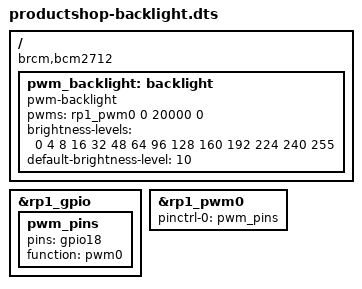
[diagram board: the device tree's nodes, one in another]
/dts-v1/;
/plugin/;

/{
    compatible = "brcm,bcm2712";

    // PWM pins
    fragment@0 {
        target = <&rp1_gpio>;
        __overlay__ {
            pwm_pins: pwm_pins {
                pins = "gpio18";
                function = "pwm0";
            };
        };
    };

    // PWM Controller
    fragment@1 {
        target = <&rp1_pwm0>;
        __overlay__ {
            pinctrl-names = "default";
            pinctrl-0 = <&pwm_pins>;
            status = "okay";
        };
    };

    // Backlight
    fragment@2 {
        target-path = "/";
        __overlay__ {
            pwm_backlight: backlight {
                compatible = "pwm-backlight";
                pwms = <&rp1_pwm0 0 20000 0>;
                brightness-levels = <0 4 8 16 32 48 64 96 128 160 192 224 240 255>;
                default-brightness-level = <10>;
                status = "okay";
            };
        };
    };
};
